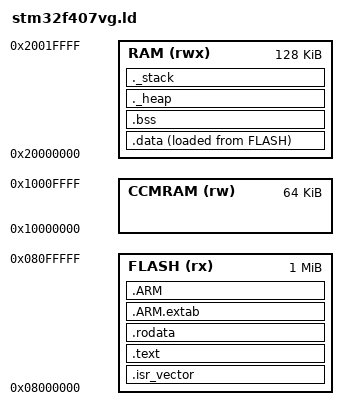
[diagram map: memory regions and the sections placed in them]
/* STM32F407VG Linker Script
 * Flash: 1MB at 0x08000000
 * RAM:   128KB at 0x20000000
 * CCM:   64KB at 0x10000000
 */

MEMORY
{
    FLASH (rx)  : ORIGIN = 0x08000000, LENGTH = 1024K
    RAM (rwx)   : ORIGIN = 0x20000000, LENGTH = 128K
    CCMRAM (rw) : ORIGIN = 0x10000000, LENGTH = 64K
}

/* Entry point */
ENTRY(Reset_Handler)

/* Stack at top of RAM */
_estack = ORIGIN(RAM) + LENGTH(RAM);

/* Minimum heap and stack sizes */
_Min_Heap_Size = 0x2000;   /* 8 KB */
_Min_Stack_Size = 0x1000;  /* 4 KB */

SECTIONS
{
    /* ISR vector table — must be at start of flash */
    .isr_vector :
    {
        . = ALIGN(4);
        KEEP(*(.isr_vector))
        . = ALIGN(4);
    } >FLASH

    /* Code */
    .text :
    {
        . = ALIGN(4);
        *(.text)
        *(.text*)
        *(.glue_7)
        *(.glue_7t)
        *(.eh_frame)
        KEEP(*(.init))
        KEEP(*(.fini))
        . = ALIGN(4);
        _etext = .;
    } >FLASH

    /* Read-only data */
    .rodata :
    {
        . = ALIGN(4);
        *(.rodata)
        *(.rodata*)
        . = ALIGN(4);
    } >FLASH

    /* ARM exception handling */
    .ARM.extab :
    {
        *(.ARM.extab* .gnu.linkonce.armextab.*)
    } >FLASH

    .ARM :
    {
        __exidx_start = .;
        *(.ARM.exidx*)
        __exidx_end = .;
    } >FLASH

    /* Initialized data — loaded from flash, copied to RAM at startup */
    _sidata = LOADADDR(.data);
    .data :
    {
        . = ALIGN(4);
        _sdata = .;
        *(.data)
        *(.data*)
        . = ALIGN(4);
        _edata = .;
    } >RAM AT> FLASH

    /* Uninitialized data (BSS) — zeroed at startup */
    .bss :
    {
        . = ALIGN(4);
        _sbss = .;
        __bss_start__ = _sbss;
        *(.bss)
        *(.bss*)
        *(COMMON)
        . = ALIGN(4);
        _ebss = .;
        __bss_end__ = _ebss;
    } >RAM

    /* Heap */
    ._heap :
    {
        . = ALIGN(8);
        __heap_start = .;
        . = . + _Min_Heap_Size;
        __heap_end = .;
        . = ALIGN(8);
    } >RAM

    /* Stack (grows down from _estack) */
    ._stack :
    {
        . = ALIGN(8);
        . = . + _Min_Stack_Size;
        . = ALIGN(8);
    } >RAM

    /* Discard debug sections for size */
    /DISCARD/ :
    {
        libc.a(*)
        libm.a(*)
        libgcc.a(*)
    }
}
